# LPC8N04 register map
File version: 0.1
CPU: CM0PLUS r0p0, little endian, no MPU, no FPU, 2 interrupt priority bits
Registers are 32-bit, read-write, no defined reset value unless marked. A register's access mark holds for its fields unless they carry their own. Offsets are from the block's base; [hi:lo] are bit positions.

## EEPROM — EEPROM controller
Base 0x40034000
0x00 EECMD — EEPROM command register
  [2:0] CMD — Writing the value 110 on this field will start ERASE/PROGRAM.
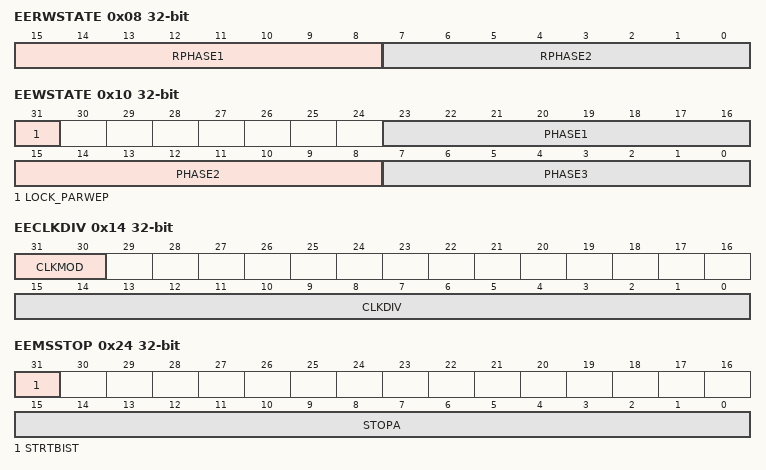
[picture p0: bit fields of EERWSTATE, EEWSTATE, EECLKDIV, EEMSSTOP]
0x08 EERWSTATE — EEPROM read wait state register
  [15:8] RPHASE1 — Duration of the EEPROM precharge phase
  [7:0] RPHASE2 — Duration of the EEPROM evaluation (read) phase
0x0C EEPAUTOPROG — EEPROM auto programming register
  [1:0] AUTOPROG — Set auto programming mode
    0=NA0 (auto programming switched off); 1=NA1 (erase/program cycle is triggered after 1 word is written); 2=NA2 (erase/program cycle is triggered after a write to the last word of a page); 3=NA3 ((reserved))
0x10 EEWSTATE — EEPROM wait state register
  [31] LOCK_PARWEP — When set, all registers used for write/program timing configuration become read only (therefore this bit can?t be written to 0 after ir has been written to 1)
  [23:16] PHASE1 — Max setup of any input w.r.t. write or program command
  [15:8] PHASE2 — Duration of the write or program command
  [7:0] PHASE3 — max hold of all signals w.r.t write or program command
0x14 EECLKDIV — EEPROM clock divider register
  [31:30] CLKMOD — Amount of clock modulation (number of bits of random value added to CLKDIV at each clock cycle)
  [15:0] CLKDIV — 0: program clock switched off; larger than0: clock division factor (-1 encoded)
0x18 EEPWRDWN — EEPROM power-down register
  [0] PWRDWN — When bit is set, power-down mode is in effect
0x20 EEMSSTART — EEPROM checksum start address register
  [15:0] STARTA — When bit is set, power-down mode is in effect
0x24 EEMSSTOP — EEPROM checksum stop address register
  [31] STRTBIST — When this bit is written to 1, signature generation starts. At the end of signature generation, this bit is automaticaaly cleared.
  [15:0] STOPA — Stop address for signature generation (the word specified by STOPA is included in the address range). The address is in units of memory words, not bytes. Bits 2:0 cannot be written and are forced to 111.
0x28 EEMSDATASIG ro — EEPROM Data signature register
  [31:0] DATA_SIG — After signature generation has run, this field contains the data signature for the specified address range.
0x2C EEMSPARSIG ro — EEPROM parity signature register
  [0] PARITY_SIG — After signature generation has run, this field contains the parity signature for the specified address range.
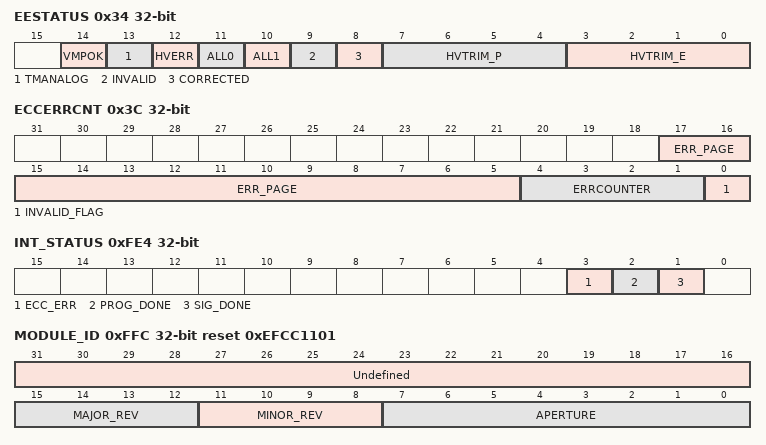
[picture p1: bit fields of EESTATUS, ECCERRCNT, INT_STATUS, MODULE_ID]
0x34 EESTATUS ro — EEPROM device status register
  [14] VMPOK — margin pump level OK
  [13] TMANALOG — analog test mode is in effect
  [12] HVERR — high voltage error
  [11] ALL0 — all bits in the last memory word read are low
  [10] ALL1 — all bits in the last memory word read are high
  [9] INVALID — ECC detected an uncorrectable error
  [8] CORRECTED — ECC detected a correctable error
  [7:4] HVTRIM_P — Trim value for the programming voltage
  [3:0] HVTRIM_E — Trim value for the erase voltage
0x38 ECCRSTERRCNT wo — Invalid flag and error corrected counter reset
  [0] ECCRSTERRCNT — When set, it clears the ECCERRCNT register. Always reads as 0.
0x3C ECCERRCNT ro — ECC status information
  [17:5] ERR_PAGE — page address of the last location containing an ECC (correctable or uncorrectable) error. Only significant if ERRCOUNTER or INVALID_FLAG are non-zero.
  [4:1] ERRCOUNTER — Incremented when an ECC correction occurs (saturates at 1111). Cleared by writing 1 into ECCRSTERRCNT.
  [0] INVALID_FLAG — Set when an uncorrectable ECC error occurs. Cleared by writing 1 into ECCRSTERRCNT
0x54 EECLKDIV1 — EEPROM initial clock divider register
  [15:0] CLKDIV1 — initial clock division factor, -1 encoded
0x58 EECLKDIV2 — EEPROM clock ramp duration register
  [15:0] CLKDIV2 — Number of program clock cycles after which the clock division factor is decremented, -1 encoded
0xFD8 INT_CLR_ENABLE wo — Clear interrupt enable bits
  [31:0] CLR_ENABLE — When a CLR_ENABLE bit is written to 1, the corresponding INT_ENABLE bit is cleared.
0xFDC INT_SET_ENABLE wo — Set interrupt enable bits
  [31:0] SET_ENABLE — When a SET_ENABLE bit is written to 1, the corresponding INT_ENABLE bit is set, unless it is a reserved bit.
0xFE0 INT_ENABLE ro — Interrupt enable bits
  [31:0] INT_ENABLE — If an INT_ENABLE bit is set, an interrupt request will be generated of the corresponding INT_STATUS bit is asserted.
0xFE4 INT_STATUS ro — Interrupt status bits
  [3] ECC_ERR — This status bit is set if, during a memory read operation (either a user-requested read, or a speculative read, or reads performed during initialization or during signature generation) a correctable or uncorrectable error is detected by ECC decoding logic.
  [2] PROG_DONE — This status bit is set at the end of a high-voltage operation (burn, erase, combined erase+program)
  [1] SIG_DONE — This status bit is set at the end of signature computation
0xFE8 INT_CLR_STATUS wo — Clear interrupt status bits
  [31:0] CLR_STATUS — When a CLR_STATUS bit is written to 1, the corresponding INT_STATUS bit is cleared.
0xFEC INT_SET_STATUS wo — Set interrupt status bits
  [31:0] SET_STATUS — When a SET_STATUS bit is written to 1, the corresponding INT_STATUS bit is set, unless it is a reserved bit.
0xFFC MODULE_ID ro reset 0xEFCC1101 (reset mask 0x0) — Controller memory module identification
  [31:16] Undefined — Identification number; unique module identifier indicating the module ID of the controller
  [15:12] MAJOR_REV — major revision of module implementation
  [11:8] MINOR_REV — Minor revision of module implementation
  [7:0] APERTURE — The size of the memory encoded as (size/4kByte) -1
